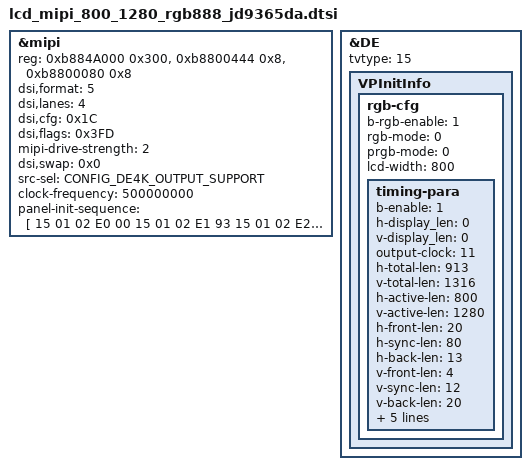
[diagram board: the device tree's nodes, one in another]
&mipi {
	reg = <0xb884A000 0x300>, <0xb8800444 0x8>,<0xb8800080 0x8>;

	/*
	 * MIPI_COLOR_RGB565_0	=	0
	 * MIPI_COLOR_RGB565_1	=	1
	 * MIPI_COLOR_RGB565_2	=	2
	 * MIPI_COLOR_RGB666_0	=	3
	 * MIPI_COLOR_RGB666_1	=	4
	 * MIPI_COLOR_RGB888	=	5
	 */
	dsi,format =<5>;

	dsi,lanes = <4>;

	/*
	 * bit 6:5 :Generic interface read-back Virtual Channel identification.
	 * bit 4 :Enables CRC reception and error reporting.
	 * bit 3 :Enables ECC reception, error correction and reporting
	 * bit 2 :MIPI_Bus_Turn_request.
	 * bit 1 :Enables EOTp reception.
	 * bit 0 :Enables EOTp transmission.
	 */
	dsi,cfg = <0x1C>;

	/* If there is no "dsi,flags", "dsi,flags" = <0x3FD>;
	 * bit 11: Enables the request for an acknowledge response at the end of a fram
	 * bit 10: Enables the transmission of null packets in the HACT period
	 * bit 9:  Enables the transmission of multi video packets in the HACT period
	 * bit 8:  Enables return to Low Power inside HFP period when timing allows.
	 * bit 7:  Enables return to Low Power inside HBP period when timing allows
	 * bit 6:  Enables return to Low Power inside VACT period when timing allows.
	 * bit 5:  Enables return to Low Power inside VFP period when timing allows
	 * bit 4:  Enables return to Low Power inside VBP period when timing allows
	 * bit 3:  Enables return to Low Power inside VSA period when timing allows
	 * bit 2:1 Selects video mode transmission type. 0: Non-burst with Sync pulses; 1: Non-burst with Sync events; 2-3: Burst with Sync pulses.
	 * bit 0:  Enables DPI Video mode transmission.
	 */
	dsi,flags = <0x3FD>;

	/*
	 * 0: MIPI_DRIVE_STRENGTH_MIDIMUN,
	 * 1: MIPI_DRIVE_STRENGTH_MIDDLE,
	 * 2: MIPI_DRIVE_STRENGTH_BIGGER, default
	 * 3: MIPI_DRIVE_STRENGTH_MAXIMUM,
	*/
	mipi-drive-strength = <2>;

	/*
	 * bit 4 : MIPI_DSI_DATA3_LANE_NP_SWAP
	 * bit 3 : MIPI_DSI_DATA2_LANE_NP_SWAP
	 * bit 2 : MIPI_DSI_DATA1_LANE_NP_SWAP
	 * bit 1 : MIPI_DSI_DATA0_LANE_NP_SWAP
	 * bit 0 : MIPI_DSI_CLOCK_LANE_NP_SWAP
	 */

	dsi,swap = <0x0>;
	/*
	 * 0: E_SRC_SEL_FXDE = 0
	 * 1: E_SRC_SEL_4KDE
	 * 2: E_SRC_SEL_HDMI_RX
	 */
	src-sel = <CONFIG_DE4K_OUTPUT_SUPPORT>;
	clock-frequency = <500000000>;
	//status = "okay";
};

&DE {
	tvtype = <15>;
	VPInitInfo {
		rgb-cfg{
			b-rgb-enable = <1>;
			/*
			 * 0: MODE_PRGB
			 * 1: MODE_SRGB
			 */
			rgb-mode = <0>;
			/*
			 * 0: MODE_PRGB_888_10bit
			 * 1: MODE_PRGB_666
			 */
			prgb-mode = <0>;
			lcd-width = <800>;
			timing-para {
				/* bool type, 0 or 1*/
				b-enable = <1>;

				h-display_len = <0>;
				v-display_len = <0>;

				/*
				 * VPO_RGB_CLOCK_27M = 1,
				 * VPO_RGB_CLOCK_33M = 2,
				 * VPO_RGB_CLOCK_49M = 3,
				 * VPO_RGB_CLOCK_66M = 4,
				 * VPO_RGB_CLOCK_74M = 5,
				 * VPO_RGB_CLOCK_85M = 6,
				 * VPO_RGB_CLOCK_108M = 7,
				 * VPO_RGB_CLOCK_6_6M = 8,
				 * VPO_RGB_CLOCK_9M = 9,
				 * VPO_RGB_CLOCK_39_6M = 10,
				 * VPO_RGB_CLOCK_74_25M = 11,
				 * VPO_RGB_CLOCK_148_5M = 12,
				 * VPO_RGB_CLOCK_54M = 13,
				 * VPO_RGB_CLOCK_132M = 14,//H1600
				 * VPO_RGB_CLOCK_297M = 15,//H1600 only De4k
				 * VPO_RGB_CLOCK_DPLL = 0xFF,//H1600
				*/
				output-clock = <11>;

				h-total-len = <913>;
				v-total-len = <1316>;

				h-active-len = <800>;
				v-active-len = <1280>;

				h-front-len = <20>;
				h-sync-len = <80>;
				h-back-len = <13>;

				v-front-len = <4>;
				v-sync-len = <12>;
				v-back-len = <20>;

				/* bool type, 0 or 1*/
				h-sync-level = <0>;
				/* bool type, 0 or 1*/
				v-sync-level = <0>;

				/* bool type, 0 or 1*/
				active-polarity = <1>;
				frame-rate = <60000>;

				/*
				31	De_dig_pll_en
				25:16	DE_DIG_PLL_M_ctrl
				13:8	DE_DIG_PLL_N_ctrl
				5:0	DE_DIG_PLL_L_ctrl
				de_digpll_clock = 24 *(M+1)/((N+1)*(L+1))
				*/
				dpll-clock-reg-value = <0x0>;
			};
		};
	};
};

&mipi{
	panel-init-sequence = [
		15 01 02 E0 00
		15 01 02 E1 93
		15 01 02 E2 65
		15 01 02 E3 F8
		15 01 02 80 03
		15 01 02 E0 01
		15 01 02 00 00
		15 01 02 01 31
		15 01 02 03 00
		15 01 02 04 31
		15 01 02 0C 74
		15 01 02 17 00
		15 01 02 18 F7
		15 01 02 19 01
		15 01 02 1A 00
		15 01 02 1B F7
		15 01 02 1C 01
		15 01 02 24 FE
		15 01 02 35 23
		15 01 02 37 09
		15 01 02 38 04
		15 01 02 39 00
		15 01 02 3A 01
		15 01 02 3C 70
		15 01 02 3D FF
		15 01 02 3E FF
		15 01 02 3F 7F
		15 01 02 40 06
		15 01 02 41 A0
		15 01 02 43 1E
		15 01 02 44 0B
		15 01 02 45 28
		15 01 02 55 02
		15 01 02 57 69
		15 01 02 59 0A
		15 01 02 5A 2D
		15 01 02 5B 19
		15 01 02 5C 15
		15 01 02 5D 7F
		15 01 02 5E 6D
		15 01 02 5F 5E
		15 01 02 60 51
		15 01 02 61 4D
		15 01 02 62 3D
		15 01 02 63 3F
		15 01 02 64 26
		15 01 02 65 3C
		15 01 02 66 39
		15 01 02 67 35
		15 01 02 68 4F
		15 01 02 69 39
		15 01 02 6A 3E
		15 01 02 6B 2F
		15 01 02 6C 2C
		15 01 02 6D 1E
		15 01 02 6E 0F
		15 01 02 6F 02
		15 01 02 70 7F
		15 01 02 71 6D
		15 01 02 72 5E
		15 01 02 73 51
		15 01 02 74 4D
		15 01 02 75 3D
		15 01 02 76 3F
		15 01 02 77 26
		15 01 02 78 3C
		15 01 02 79 39
		15 01 02 7A 35
		15 01 02 7B 4F
		15 01 02 7C 39
		15 01 02 7D 3E
		15 01 02 7E 2F
		15 01 02 7F 2C
		15 01 02 80 1E
		15 01 02 81 0F
		15 01 02 82 02
		15 01 02 E0 02
		15 01 02 00 50
		15 01 02 01 5F
		15 01 02 02 5F
		15 01 02 03 52
		15 01 02 04 77
		15 01 02 05 57
		15 01 02 06 5F
		15 01 02 07 4E
		15 01 02 08 4C
		15 01 02 09 5F
		15 01 02 0A 4A
		15 01 02 0B 48
		15 01 02 0C 5F
		15 01 02 0D 46
		15 01 02 0E 44
		15 01 02 0F 40
		15 01 02 10 5F
		15 01 02 11 5F
		15 01 02 12 5F
		15 01 02 13 5F
		15 01 02 14 5F
		15 01 02 15 5F
		15 01 02 16 51
		15 01 02 17 5F
		15 01 02 18 5F
		15 01 02 19 53
		15 01 02 1A 77
		15 01 02 1B 57
		15 01 02 1C 5F
		15 01 02 1D 4F
		15 01 02 1E 4D
		15 01 02 1F 5F
		15 01 02 20 4B
		15 01 02 21 49
		15 01 02 22 5F
		15 01 02 23 47
		15 01 02 24 45
		15 01 02 25 41
		15 01 02 26 5F
		15 01 02 27 5F
		15 01 02 28 5F
		15 01 02 29 5F
		15 01 02 2A 5F
		15 01 02 2B 5F
		15 01 02 2C 01
		15 01 02 2D 1F
		15 01 02 2E 1F
		15 01 02 2F 13
		15 01 02 30 17
		15 01 02 31 17
		15 01 02 32 1F
		15 01 02 33 0D
		15 01 02 34 0F
		15 01 02 35 1F
		15 01 02 36 05
		15 01 02 37 07
		15 01 02 38 1F
		15 01 02 39 09
		15 01 02 3A 0B
		15 01 02 3B 11
		15 01 02 3C 1F
		15 01 02 3D 1F
		15 01 02 3E 1F
		15 01 02 3F 1F
		15 01 02 40 1F
		15 01 02 41 1F
		15 01 02 42 00
		15 01 02 43 1F
		15 01 02 44 1F
		15 01 02 45 12
		15 01 02 46 17
		15 01 02 47 17
		15 01 02 48 1F
		15 01 02 49 0C
		15 01 02 4A 0E
		15 01 02 4B 1F
		15 01 02 4C 04
		15 01 02 4D 06
		15 01 02 4E 1F
		15 01 02 4F 08
		15 01 02 50 0A
		15 01 02 51 10
		15 01 02 52 1F
		15 01 02 53 1F
		15 01 02 54 1F
		15 01 02 55 1F
		15 01 02 56 1F
		15 01 02 57 1F
		15 01 02 58 40
		15 01 02 5B 10
		15 01 02 5C 06
		15 01 02 5D 40
		15 01 02 5E 00
		15 01 02 5F 00
		15 01 02 60 40
		15 01 02 61 03
		15 01 02 62 04
		15 01 02 63 6C
		15 01 02 64 6C
		15 01 02 65 75
		15 01 02 66 08
		15 01 02 67 B4
		15 01 02 68 08
		15 01 02 69 6C
		15 01 02 6A 6C
		15 01 02 6B 0C
		15 01 02 6D 00
		15 01 02 6E 00
		15 01 02 6F 88
		15 01 02 75 BB
		15 01 02 76 00
		15 01 02 77 05
		15 01 02 78 2A
		15 01 02 E0 04
		15 01 02 02 23
		15 01 02 09 11
		15 01 02 0E 48
		15 01 02 36 49
		15 01 02 E0 00
		05 78 01 11
		05 05 01 29
	];
};
